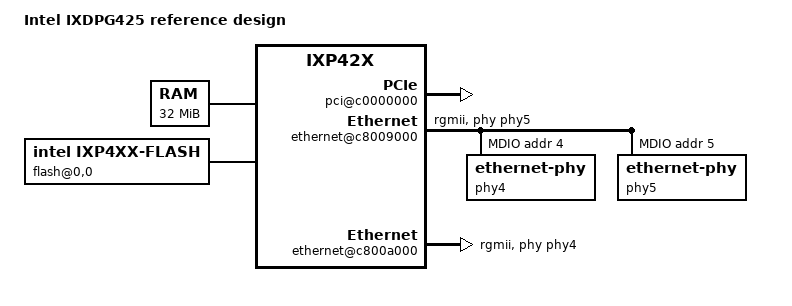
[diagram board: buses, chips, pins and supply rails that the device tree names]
/dts-v1/;
#include "intel-ixp42x.dtsi"
#include <dt-bindings/input/input.h>
/ {
	model = "Intel IXDPG425 reference design";
	compatible = "intel,ixdpg425", "intel,ixp42x";
	#address-cells = <1>;
	#size-cells = <1>;
	memory@0 {
		device_type = "memory";
		reg = <0x00000000 0x02000000>;
	};
	chosen {
		bootargs = "console=ttyS0,115200n8 root=/dev/sda1 rw rootwait";
		stdout-path = "uart0:115200n8";
	};
	aliases {
		serial0 = &uart0;
	};
	soc {
		bus@c4000000 {
			flash@0,0 {
				compatible = "intel,ixp4xx-flash", "cfi-flash";
				bank-width = <2>;
				reg = <0 0x00000000 0x1000000>;
				intel,ixp4xx-eb-write-enable = <1>;
				partitions {
					compatible = "redboot-fis";
					fis-index-block = <0x7f>;
				};
			};
		};
		pci@c0000000 {
			status = "okay";
			#interrupt-cells = <1>;
			interrupt-map-mask = <0xf800 0 0 7>;
			interrupt-map =
			<0x6000 0 0 1 &gpio0 7 IRQ_TYPE_LEVEL_LOW>,  
			<0x6000 0 0 2 &gpio0 7 IRQ_TYPE_LEVEL_LOW>,  
			<0x6000 0 0 3 &gpio0 7 IRQ_TYPE_LEVEL_LOW>,  
			<0x6000 0 0 4 &gpio0 7 IRQ_TYPE_LEVEL_LOW>,  
			<0x6800 0 0 1 &gpio0 7 IRQ_TYPE_LEVEL_LOW>,  
			<0x6800 0 0 2 &gpio0 7 IRQ_TYPE_LEVEL_LOW>,  
			<0x6800 0 0 3 &gpio0 7 IRQ_TYPE_LEVEL_LOW>,  
			<0x6800 0 0 4 &gpio0 7 IRQ_TYPE_LEVEL_LOW>,  
			<0x7000 0 0 1 &gpio0 6 IRQ_TYPE_LEVEL_LOW>,  
			<0x7000 0 0 2 &gpio0 6 IRQ_TYPE_LEVEL_LOW>,  
			<0x7000 0 0 3 &gpio0 6 IRQ_TYPE_LEVEL_LOW>,  
			<0x7000 0 0 4 &gpio0 6 IRQ_TYPE_LEVEL_LOW>;  
		};
		ethernet@c8009000 {
			status = "okay";
			queue-rx = <&qmgr 3>;
			queue-txready = <&qmgr 20>;
			phy-mode = "rgmii";
			phy-handle = <&phy5>;
			mdio {
				#address-cells = <1>;
				#size-cells = <0>;
				phy4: ethernet-phy@4 {
					reg = <4>;
				};
				phy5: ethernet-phy@5 {
					reg = <5>;
				};
			};
		};
		ethernet@c800a000 {
			status = "okay";
			queue-rx = <&qmgr 4>;
			queue-txready = <&qmgr 21>;
			phy-mode = "rgmii";
			phy-handle = <&phy4>;
		};
	};
};
